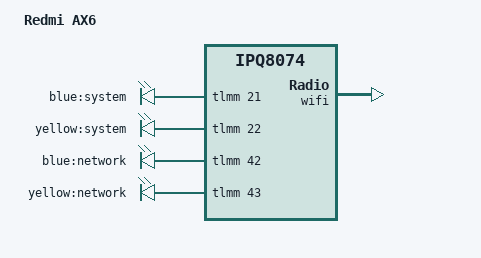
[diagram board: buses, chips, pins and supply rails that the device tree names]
// SPDX-License-Identifier: GPL-2.0-or-later OR MIT
/* Copyright (c) 2021, Zhijun You <hujy652@gmail.com> */

/dts-v1/;

#include "ipq8071-xiaomi.dtsi"

/ {
	model = "Redmi AX6";
	compatible = "redmi,ax6", "qcom,ipq8074";

	leds {
		compatible = "gpio-leds";

		led_system_blue: system-blue {
			label = "blue:system";
			gpios = <&tlmm 21 GPIO_ACTIVE_HIGH>;
		};

		led_system_yellow: system-yellow {
			label = "yellow:system";
			gpios = <&tlmm 22 GPIO_ACTIVE_HIGH>;
		};

		network-blue {
			label = "blue:network";
			gpios = <&tlmm 42 GPIO_ACTIVE_HIGH>;
		};

		network-yellow {
			label = "yellow:network";
			gpios = <&tlmm 43 GPIO_ACTIVE_HIGH>;
		};
	};
};

/* AX6 can both have NAND of 256MiB or 128MiB.
 * To be on the safe side, assume 128MiB of NAND.
 */
&rootfs {
	reg = <0x2dc0000 0x5220000>;
};

&wifi {
	status = "okay";
	qcom,ath11k-fw-memory-mode = <1>;
	qcom,ath11k-calibration-variant = "Redmi-AX6";
	qcom,nss-wifili-tx-desc-count = <16384>;
};

/* Redmi AX6 / IPQ8071A: stock firmware caps NSS at 1,497.6 MHz */
&nss0 {
	qcom,max-frequency = <1497600000>;
};

/* AX6 has no exposed USB/PCIe/SPI peripherals. Disabling the unused
 * controllers avoids gcc sync_state consumers that keep resetting EDMA RPS.
 */
&usb_0 { status = "disabled"; };
&usb_1 { status = "disabled"; };
&qusb_phy_0 { status = "disabled"; };
&qusb_phy_1 { status = "disabled"; };
&ssphy_0 { status = "disabled"; };
&ssphy_1 { status = "disabled"; };
&pcie_qmp0 { status = "disabled"; };
&pcie_qmp1 { status = "disabled"; };
&pcie0 { status = "disabled"; };
&pcie1 { status = "disabled"; };
&blsp1_spi1 { status = "disabled"; };
